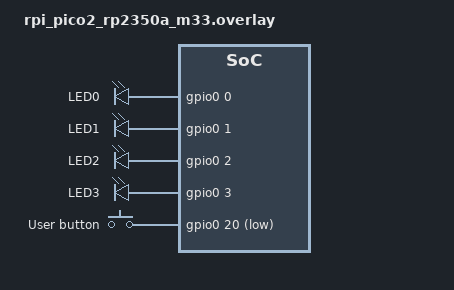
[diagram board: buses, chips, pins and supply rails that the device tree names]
/ {
    aliases {
        led0 = &led0;
        led1 = &led1;
        led2 = &led2;
        led3 = &led3;
        btn  = &button0;
    };

    leds {
        compatible = "gpio-leds";
        led0: led_0 {
            gpios = <&gpio0 0 GPIO_ACTIVE_HIGH>;
            label = "LED0";
        };
        led1: led_1 {
            gpios = <&gpio0 1 GPIO_ACTIVE_HIGH>;
            label = "LED1";
        };
        led2: led_2 {
            gpios = <&gpio0 2 GPIO_ACTIVE_HIGH>;
            label = "LED2";
        };
        led3: led_3 {
            gpios = <&gpio0 3 GPIO_ACTIVE_HIGH>;
            label = "LED3";
        };
    };

    buttons {
        compatible = "gpio-keys";
        button0: button_0 {
            gpios = <&gpio0 20  GPIO_ACTIVE_LOW>; 
            label = "User button";
        };
    };
};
